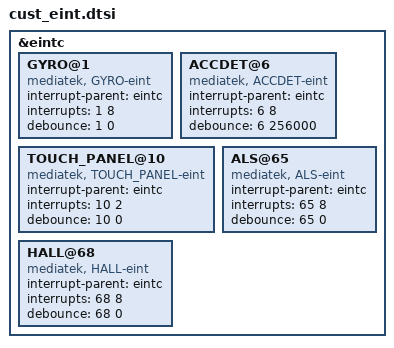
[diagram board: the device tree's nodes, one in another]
/*
 * Generated by MTK SP DrvGen Version 03.13.6 for MT6753. Copyright MediaTek Inc. (C) 2013.
 * Sat Jun 27 16:09:47 2015
 * Do Not Modify the File.
 */

/*************************
 * EINT DTSI File
*************************/

&eintc {
	GYRO@1 {
		compatible = "mediatek, GYRO-eint";
		interrupt-parent = <&eintc>;
		interrupts = <1 8>;
		debounce = <1 0>;
	};

	ACCDET@6 {
		compatible = "mediatek, ACCDET-eint";
		interrupt-parent = <&eintc>;
		interrupts = <6 8>;
		debounce = <6 256000>;
	};

	TOUCH_PANEL@10 {
		compatible = "mediatek, TOUCH_PANEL-eint";
		interrupt-parent = <&eintc>;
		interrupts = <10 2>;
		debounce = <10 0>;
	};

	ALS@65 {
		compatible = "mediatek, ALS-eint";
		interrupt-parent = <&eintc>;
		interrupts = <65 8>;
		debounce = <65 0>;
	};

	HALL@68 {
		compatible = "mediatek, HALL-eint";
		interrupt-parent = <&eintc>;
		interrupts = <68 8>;
		debounce = <68 0>;
	};

};
